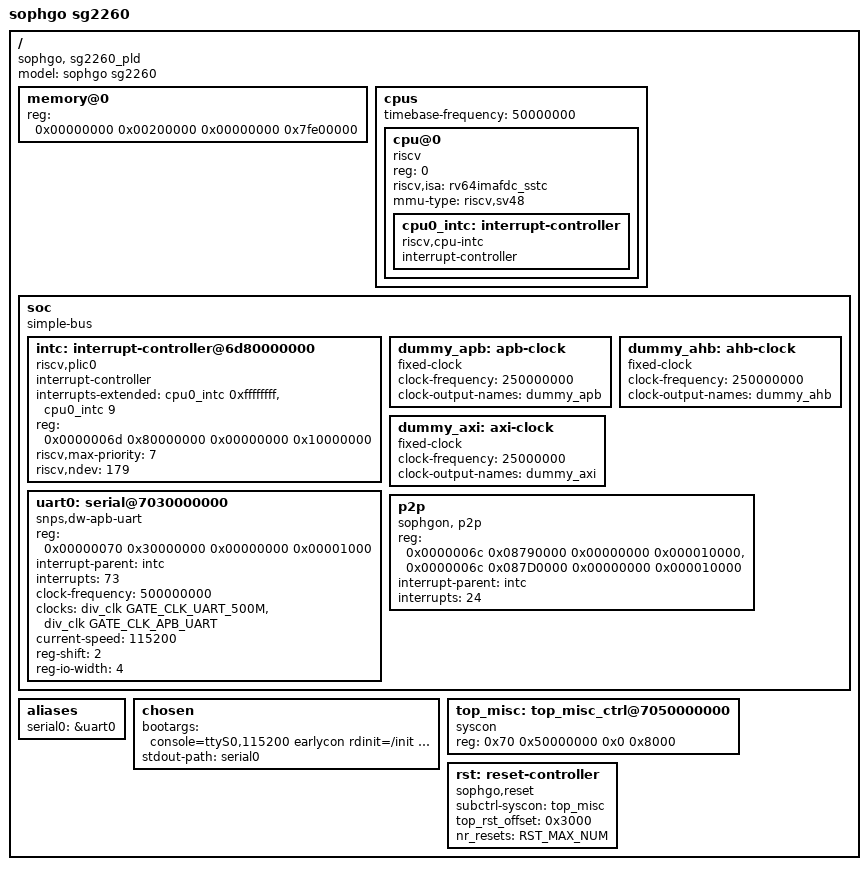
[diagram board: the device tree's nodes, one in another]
// SPDX-License-Identifier: (GPL-2.0 OR MIT)
/*
 * Copyright (C) 2022 Sophgo Technology Inc. All rights reserved.
 */

/dts-v1/;
#include <dt-bindings/reset/sophgo,sg2044-reset.h>
#include <dt-bindings/clock/sophgo,sg2044-clock.h>
#include "sg2044-clock.dtsi"
#include "sg2044-pinctrl.dtsi"

/ {
	model = "sophgo sg2260";
	compatible = "sophgo, sg2260_pld";
	#address-cells = <2>;
	#size-cells = <2>;

	memory@0 {
		device_type = "memory";
		reg = <0x00000000 0x00200000 0x00000000 0x7fe00000>;
	};

	cpus {
		#address-cells = <1>;
		#size-cells = <0>;
		timebase-frequency = <50000000>;
		cpu@0 {
			device_type = "cpu";
			reg = <0>;
			status = "okay";
			compatible = "riscv";
			riscv,isa = "rv64imafdc_sstc";
			mmu-type = "riscv,sv48";
			cpu0_intc: interrupt-controller {
				#interrupt-cells = <1>;
				compatible = "riscv,cpu-intc";
				interrupt-controller;
			};
		};
	};

	soc {
		#address-cells = <2>;
		#size-cells = <2>;
		compatible = "simple-bus";
		ranges;

		//1cores PLIC1
		intc: interrupt-controller@6d80000000 {
			#interrupt-cells = <1>;
			compatible = "riscv,plic0";
			interrupt-controller;
			interrupts-extended = <
				&cpu0_intc  0xffffffff &cpu0_intc  9
				>;
			reg = <0x0000006d 0x80000000 0x00000000 0x10000000>;
			reg-names = "control";
			riscv,max-priority = <7>;
			riscv,ndev = <179>;
		};

		dummy_apb: apb-clock {
			compatible = "fixed-clock";
			clock-frequency = <250000000>;
			clock-output-names = "dummy_apb";
			#clock-cells = <0>;
		};

		dummy_ahb: ahb-clock {
			compatible = "fixed-clock";
			clock-frequency = <250000000>;
			clock-output-names = "dummy_ahb";
			#clock-cells = <0>;
		};

		dummy_axi: axi-clock {
			compatible = "fixed-clock";
			clock-frequency = <25000000>;
			clock-output-names = "dummy_axi";
			#clock-cells = <0>;
		};

		uart0: serial@7030000000 {
			compatible = "snps,dw-apb-uart";
			reg = <0x00000070 0x30000000 0x00000000 0x00001000>;
			interrupt-parent = <&intc>;
			interrupts = <73>;
			clock-frequency = <500000000>;
			clocks = <&div_clk GATE_CLK_UART_500M>,
					 <&div_clk GATE_CLK_APB_UART>;
			clock-names = "baudclk", "apb_pclk";
			current-speed = <115200>;
			reg-shift = <2>;
			reg-io-width = <4>;
		};

		p2p:  p2p {
			compatible = "sophgon, p2p";
			reg = <0x0000006c 0x08790000 0x00000000 0x000010000>,
			      <0x0000006c 0x087D0000 0x00000000 0x000010000>;
			reg-names = "cdma_cfg","cxp_top_cfg";
			interrupt-parent = <&intc>;
			interrupts = <24>;
			interrupt-names = "CXP_CDMA0";
		};

	};

	aliases {
		serial0 = &uart0;
	};

	chosen {
		bootargs = "console=ttyS0,115200 earlycon rdinit=/init root=/dev/ram0 rw initrd=0x30000000,32M rdmem=0x80000000,2040M no5lvl";
		stdout-path = "serial0";
	};

	top_misc: top_misc_ctrl@7050000000 {
		compatible = "syscon";
		reg = <0x70 0x50000000 0x0 0x8000>;
	};

	rst: reset-controller {
		#reset-cells = <1>;
		compatible = "sophgo,reset";
		subctrl-syscon = <&top_misc>;
		top_rst_offset = <0x3000>;
		nr_resets = <RST_MAX_NUM>;
	};
};
